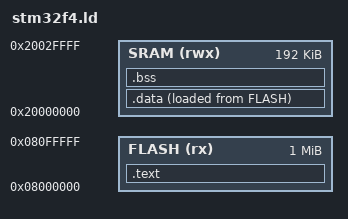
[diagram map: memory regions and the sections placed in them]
/* stm32f4.ld - minimal linker script for STM32F407 */
MEMORY
{
    FLASH (rx) : ORIGIN = 0x08000000, LENGTH = 1024K
    SRAM  (rwx) : ORIGIN = 0x20000000, LENGTH = 192K
}

SECTIONS
{
    .text :
    {
        KEEP(*(.vectors))
        *(.text*)
        *(.rodata*)
    } > FLASH

    .data :
    {
        *(.data*)
    } > SRAM AT > FLASH

    .bss :
    {
        *(.bss*)
    } > SRAM
}
